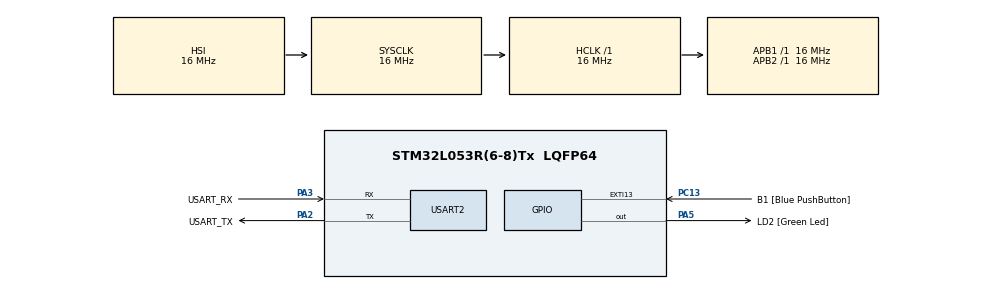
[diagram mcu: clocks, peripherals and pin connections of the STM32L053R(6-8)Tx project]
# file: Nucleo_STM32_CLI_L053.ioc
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FREERTOS.Tasks01=defaultTask,0,128,StartDefaultTask
FREERTOS.configGENERATE_RUN_TIME_STATS=1
Mcu.Family=STM32L0
Mcu.Name=STM32L053R(6-8)Tx
Mcu.Package=LQFP64
NVIC.USART2_IRQn=true\:3\:0\:false
PA13.GPIO_Label=TMS
PA13.Mode=Serial_Wire
PA13.Signal=SYS_SWDIO
PA14.GPIO_Label=TCK
PA14.Mode=Serial_Wire
PA14.Signal=SYS_SWCLK
PA2.GPIO_Label=USART_TX
PA2.GPIO_Mode=GPIO_MODE_AF_PP
PA2.GPIO_PuPd=GPIO_PULLUP
PA2.GPIO_Speed=GPIO_SPEED_LOW
PA2.Mode=Asynchronous
PA2.Signal=USART2_TX
PA3.GPIO_Label=USART_RX
PA3.GPIO_Mode=GPIO_MODE_AF_PP
PA3.GPIO_PuPd=GPIO_PULLUP
PA3.GPIO_Speed=GPIO_SPEED_LOW
PA3.Mode=Asynchronous
PA3.Signal=USART2_RX
PA5.GPIO_Label=LD2 [Green Led]
PA5.GPIO_ModeDefaultOutputPP=GPIO_MODE_OUTPUT_PP
PA5.GPIO_PuPd=GPIO_NOPULL
PA5.GPIO_Speed=GPIO_SPEED_LOW
PA5.Signal=GPIO_Output
PC13.GPIO_Label=B1 [Blue PushButton]
PC13.GPIO_ModeDefaultEXTI=GPIO_MODE_EVT_RISING
PC13.GPIO_PuPd=GPIO_NOPULL
PC13.Signal=GPXTI13
PC14-OSC32_IN.Mode=LSE-External-Oscillator
PC14-OSC32_IN.Signal=RCC_OSC32_IN
PC15-OSC32_OUT.Mode=LSE-External-Oscillator
PC15-OSC32_OUT.Signal=RCC_OSC32_OUT
PH0-OSC_IN.Signal=RCC_OSC_IN
PH1-OSC_OUT.Signal=RCC_OSC_OUT
ProjectManager.TargetToolchain=EWARM
RCC.AHBFreq_Value=16000000
RCC.APB1Freq_Value=16000000
RCC.APB1TimFreq_Value=16000000
RCC.APB2Freq_Value=16000000
RCC.APB2TimFreq_Value=16000000
RCC.HCLKFreq_Value=16000000
RCC.HSE_VALUE=8000000
RCC.HSI16_VALUE=16000000
RCC.HSI48_VALUE=48000000
RCC.HSI_VALUE=16000000
RCC.MSI_VALUE=2097000
RCC.SYSCLKFreq_VALUE=16000000
RCC.SYSCLKSource=RCC_SYSCLKSOURCE_HSI
RCC.VCOOutputFreq_Value=48000000
USART2.WordLength=UART_WORDLENGTH_8B
VP_FREERTOS_VS_ENABLE.Mode=Enabled

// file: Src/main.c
/**
  ******************************************************************************
  * File Name          : main.c
  * Date               : 19/05/2015 13:55:08
  * Description        : Main program body
  ******************************************************************************
  *
  * COPYRIGHT(c) 2015 STMicroelectronics
  *
  * Redistribution and use in source and binary forms, with or without modification,
  * are permitted provided that the following conditions are met:
  *   1. Redistributions of source code must retain the above copyright notice,
  *      this list of conditions and the following disclaimer.
  *   2. Redistributions in binary form must reproduce the above copyright notice,
  *      this list of conditions and the following disclaimer in the documentation
  *      and/or other materials provided with the distribution.
  *   3. Neither the name of STMicroelectronics nor the names of its contributors
  *      may be used to endorse or promote products derived from this software
  *      without specific prior written permission.
  *
  * THIS SOFTWARE IS PROVIDED BY THE COPYRIGHT HOLDERS AND CONTRIBUTORS "AS IS"
  * AND ANY EXPRESS OR IMPLIED WARRANTIES, INCLUDING, BUT NOT LIMITED TO, THE
  * IMPLIED WARRANTIES OF MERCHANTABILITY AND FITNESS FOR A PARTICULAR PURPOSE ARE
  * DISCLAIMED. IN NO EVENT SHALL THE COPYRIGHT HOLDER OR CONTRIBUTORS BE LIABLE
  * FOR ANY DIRECT, INDIRECT, INCIDENTAL, SPECIAL, EXEMPLARY, OR CONSEQUENTIAL
  * DAMAGES (INCLUDING, BUT NOT LIMITED TO, PROCUREMENT OF SUBSTITUTE GOODS OR
  * SERVICES; LOSS OF USE, DATA, OR PROFITS; OR BUSINESS INTERRUPTION) HOWEVER
  * CAUSED AND ON ANY THEORY OF LIABILITY, WHETHER IN CONTRACT, STRICT LIABILITY,
  * OR TORT (INCLUDING NEGLIGENCE OR OTHERWISE) ARISING IN ANY WAY OUT OF THE USE
  * OF THIS SOFTWARE, EVEN IF ADVISED OF THE POSSIBILITY OF SUCH DAMAGE.
  *
  ******************************************************************************
  */

#include "stm32l0xx_hal.h"
#include "cmsis_os.h"

/* USER CODE BEGIN Includes */
#include "stdio.h"

#include "string.h"

/* USER CODE END Includes */

UART_HandleTypeDef huart2;

osThreadId defaultTaskHandle;

void SystemClock_Config(void);
static void MX_GPIO_Init(void);
static void MX_USART2_UART_Init(void);
void StartDefaultTask(void const * argument);

/* USER CODE BEGIN 0 */
uint8_t UART_TX_BUFF[100];
uint8_t UART_RX_BUFF[100];

extern void vUARTCommandConsoleStart( void );
/* USER CODE END 0 */

int main(void)
{

  /* MCU Configuration----------------------------------------------------------*/

  /* Reset of all peripherals, Initializes the Flash interface and the Systick. */
  HAL_Init();

  /* Configure the system clock */
  SystemClock_Config();

  /* Initialize all configured peripherals */
  MX_GPIO_Init();
  MX_USART2_UART_Init();

  /* USER CODE BEGIN 2 */
  /* Register two command line commands to show task stats and run time stats
  respectively. */
  vRegisterCLICommands();

  /* USER CODE END 2 */

  /* Create the thread(s) */
  /* definition and creation of defaultTask */
  osThreadDef(defaultTask, StartDefaultTask, osPriorityNormal, 0, 128);
  defaultTaskHandle = osThreadCreate(osThread(defaultTask), NULL);

  /* USER CODE BEGIN RTOS_THREADS */
  /* add threads, ... */

  /* Start the tasks that implements the command console on the UART, as
  described above. */
  vUARTCommandConsoleStart();

  /* USER CODE END RTOS_THREADS */

  /* Start scheduler */
  osKernelStart(NULL, NULL);

  /* We should never get here as control is now taken by the scheduler */

  /* Infinite loop */
  while (1)
  {

  }

}

/** System Clock Configuration
*/
void SystemClock_Config(void)
{

  RCC_OscInitTypeDef RCC_OscInitStruct;
  RCC_ClkInitTypeDef RCC_ClkInitStruct;
  RCC_PeriphCLKInitTypeDef PeriphClkInit;

  __PWR_CLK_ENABLE();

  __HAL_PWR_VOLTAGESCALING_CONFIG(PWR_REGULATOR_VOLTAGE_SCALE1);

  RCC_OscInitStruct.OscillatorType = RCC_OSCILLATORTYPE_HSI;
  RCC_OscInitStruct.HSIState = RCC_HSI_ON;
  RCC_OscInitStruct.HSICalibrationValue = 16;
  RCC_OscInitStruct.PLL.PLLState = RCC_PLL_NONE;
  HAL_RCC_OscConfig(&RCC_OscInitStruct);

  RCC_ClkInitStruct.ClockType = RCC_CLOCKTYPE_SYSCLK;
  RCC_ClkInitStruct.SYSCLKSource = RCC_SYSCLKSOURCE_HSI;
  RCC_ClkInitStruct.AHBCLKDivider = RCC_SYSCLK_DIV1;
  RCC_ClkInitStruct.APB1CLKDivider = RCC_HCLK_DIV1;
  RCC_ClkInitStruct.APB2CLKDivider = RCC_HCLK_DIV1;
  HAL_RCC_ClockConfig(&RCC_ClkInitStruct, FLASH_LATENCY_0);

  PeriphClkInit.PeriphClockSelection = RCC_PERIPHCLK_USART2;
  PeriphClkInit.Usart2ClockSelection = RCC_USART2CLKSOURCE_PCLK1;
  HAL_RCCEx_PeriphCLKConfig(&PeriphClkInit);

  __SYSCFG_CLK_ENABLE();

}

/* USART2 init function */
void MX_USART2_UART_Init(void)
{

  huart2.Instance = USART2;
  huart2.Init.BaudRate = 115200;
  huart2.Init.WordLength = UART_WORDLENGTH_8B;
  huart2.Init.StopBits = UART_STOPBITS_1;
  huart2.Init.Parity = UART_PARITY_NONE;
  huart2.Init.Mode = UART_MODE_TX_RX;
  huart2.Init.HwFlowCtl = UART_HWCONTROL_NONE;
  huart2.Init.OverSampling = UART_OVERSAMPLING_16;
  huart2.Init.OneBitSampling = UART_ONEBIT_SAMPLING_DISABLED;
  huart2.AdvancedInit.AdvFeatureInit = UART_ADVFEATURE_NO_INIT;
  HAL_UART_Init(&huart2);

}

/** Configure pins as
        * Analog
        * Input
        * Output
        * EVENT_OUT
        * EXTI
*/
void MX_GPIO_Init(void)
{

  GPIO_InitTypeDef GPIO_InitStruct;

  /* GPIO Ports Clock Enable */
  __GPIOC_CLK_ENABLE();
  __GPIOH_CLK_ENABLE();
  __GPIOA_CLK_ENABLE();

  /*Configure GPIO pin : PC13 */
  GPIO_InitStruct.Pin = GPIO_PIN_13;
  GPIO_InitStruct.Mode = GPIO_MODE_EVT_RISING;
  GPIO_InitStruct.Pull = GPIO_NOPULL;
  HAL_GPIO_Init(GPIOC, &GPIO_InitStruct);

  /*Configure GPIO pin : PA5 */
  GPIO_InitStruct.Pin = GPIO_PIN_5;
  GPIO_InitStruct.Mode = GPIO_MODE_OUTPUT_PP;
  GPIO_InitStruct.Pull = GPIO_NOPULL;
  GPIO_InitStruct.Speed = GPIO_SPEED_LOW;
  HAL_GPIO_Init(GPIOA, &GPIO_InitStruct);

}

/* StartDefaultTask function */
void StartDefaultTask(void const * argument)
{

  /* USER CODE BEGIN 5 */
  /* Infinite loop */
  for(;;)
  {
//    HAL_GPIO_TogglePin(GPIOA ,GPIO_PIN_5);
//    sprintf( (char *)UART_TX_BUFF, "test" );
//    strncat( ( char * ) UART_TX_BUFF, "\r\n", strlen( "\r\n" ) );
//
//    uint8_t len = strlen( (const char *) UART_TX_BUFF);
//
//    HAL_UART_Transmit_IT(&huart2,UART_TX_BUFF, len);
    osDelay(1000);
  }
  /* USER CODE END 5 */
}

/************************ (C) COPYRIGHT STMicroelectronics *****END OF FILE****/

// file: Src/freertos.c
/**
  ******************************************************************************
  * File Name          : freertos.c
  * Date               : 19/05/2015 13:55:07
  * Description        : Code for freertos applications
  ******************************************************************************
  *
  * COPYRIGHT(c) 2015 STMicroelectronics
  *
  * Redistribution and use in source and binary forms, with or without modification,
  * are permitted provided that the following conditions are met:
  *   1. Redistributions of source code must retain the above copyright notice,
  *      this list of conditions and the following disclaimer.
  *   2. Redistributions in binary form must reproduce the above copyright notice,
  *      this list of conditions and the following disclaimer in the documentation
  *      and/or other materials provided with the distribution.
  *   3. Neither the name of STMicroelectronics nor the names of its contributors
  *      may be used to endorse or promote products derived from this software
  *      without specific prior written permission.
  *
  * THIS SOFTWARE IS PROVIDED BY THE COPYRIGHT HOLDERS AND CONTRIBUTORS "AS IS"
  * AND ANY EXPRESS OR IMPLIED WARRANTIES, INCLUDING, BUT NOT LIMITED TO, THE
  * IMPLIED WARRANTIES OF MERCHANTABILITY AND FITNESS FOR A PARTICULAR PURPOSE ARE
  * DISCLAIMED. IN NO EVENT SHALL THE COPYRIGHT HOLDER OR CONTRIBUTORS BE LIABLE
  * FOR ANY DIRECT, INDIRECT, INCIDENTAL, SPECIAL, EXEMPLARY, OR CONSEQUENTIAL
  * DAMAGES (INCLUDING, BUT NOT LIMITED TO, PROCUREMENT OF SUBSTITUTE GOODS OR
  * SERVICES; LOSS OF USE, DATA, OR PROFITS; OR BUSINESS INTERRUPTION) HOWEVER
  * CAUSED AND ON ANY THEORY OF LIABILITY, WHETHER IN CONTRACT, STRICT LIABILITY,
  * OR TORT (INCLUDING NEGLIGENCE OR OTHERWISE) ARISING IN ANY WAY OUT OF THE USE
  * OF THIS SOFTWARE, EVEN IF ADVISED OF THE POSSIBILITY OF SUCH DAMAGE.
  *
  ******************************************************************************
  */

#include "FreeRTOS.h"
#include "task.h"

/* Hook prototypes */
void configureTimerForRunTimeStats(void);
unsigned long getRunTimeCounterValue(void);

/* USER CODE BEGIN 1 */
/* Functions needed when configGENERATE_RUN_TIME_STATS is on */
void configureTimerForRunTimeStats(void)
{

}

unsigned long getRunTimeCounterValue(void)
{
return 0;
}
/* USER CODE END 1 */

/************************ (C) COPYRIGHT STMicroelectronics *****END OF FILE****/
